# STM32WB30CEU6A register map
File version: 1.0
Registers are 32-bit, access not given, reset 0x0 unless marked. A register's access mark holds for its fields unless they carry their own. Offsets are from the block's base; [hi:lo] are bit positions; {n}, {i} and the like mark numbered series.

## SYSCFG
Base 0x40010000
Same registers: SYSCFG 0x40010100, SYSCFG 0x40010100
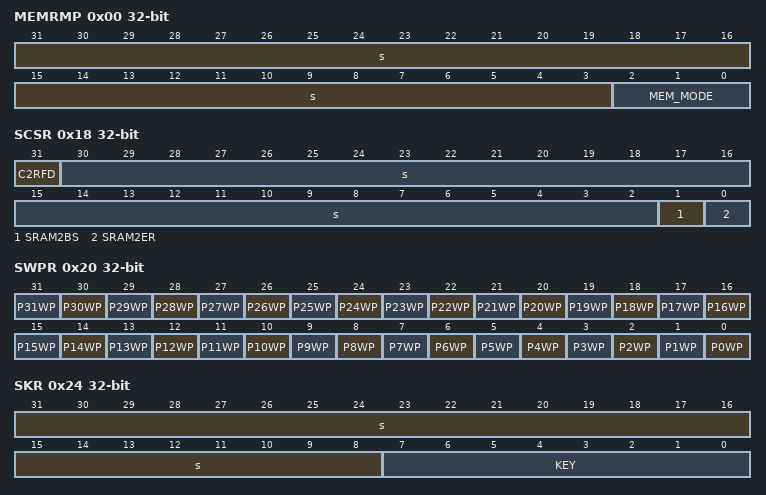
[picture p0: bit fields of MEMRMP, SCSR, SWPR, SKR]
0x00 MEMRMP
  [31:3] s, [2:0] MEM_MODE
0x04 CFGR1
  [31:26] FPU_IE, [20] I2C1_FMP, [n+10] I2C_PB{n}_FMP (n=6..9), [8] BOOSTEN, [25:0] s
0x08 EXTICR1
  [4n+2:4n] EXTI{n} (n=0..3), [31:3] s
0x0C EXTICR2
  [4n-14:4n-16] EXTI{n} (n=4..7), [31:3] s
0x10 EXTICR3
  [4n-30:4n-32] EXTI{n} (n=8..11), [31:3] s
0x14 EXTICR4
  [4n-46:4n-48] EXTI{n} (n=12..15), [31:3] s
0x18 SCSR
  [31] C2RFD, [30:2] s, [1] SRAM2BS, [0] SRAM2ER
0x1C CFGR2
  [8] SPF, [31:4] s, [3] ECCL, [2] PVDL, [1] SPL, [0] CLL
0x20 SWPR
  [n] P{n}WP (n=0..31)
0x24 SKR
  [31:8] s, [7:0] KEY
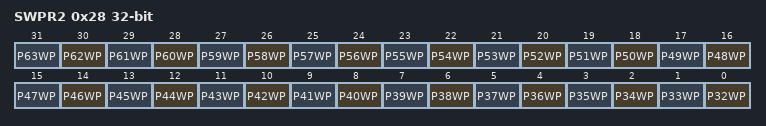
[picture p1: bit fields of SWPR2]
0x28 SWPR2
  [n-32] P{n}WP (n=32..63)
0x100 IMR1
  [n+16] EXTI{n}IM (n=5..15), [15] TIM17IM, [14] TIM16IM, [13] TIM1IM, [20:0] s
0x104 IMR2
  [20] PVDIM, [31:0] s
0x108 C2IMR1
  [n+16] EXTI{n}IM (n=0..15), [12] ADCIM, [9] RNGIM, [8] PKAIM, [6] FLASHIM, [5] RCCIM, [4] RTCALARMIM, [3] RTCWKUPIM, [15:1] s, [0] RTCSTAMPTAMPLSECSSIM
0x10C C2IMR2
  [20] PVDIM, [15] DMAMUX1IM, [31:7] s, [n-1] DMA1CH{n}IM (n=1..7)
0x110 SIPCR
  [3] SRNG, [2] SPKA, [1] SAES2, [31:0] s

## SPI1
Base 0x40013000
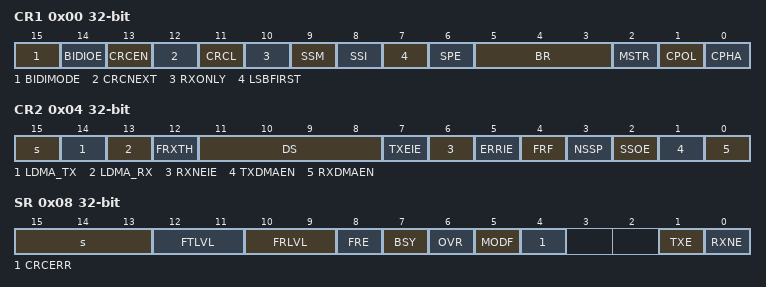
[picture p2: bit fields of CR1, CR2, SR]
0x00 CR1
  [15] BIDIMODE, [14] BIDIOE, [13] CRCEN, [12] CRCNEXT, [11] CRCL, [10] RXONLY, [9] SSM, [8] SSI, [7] LSBFIRST, [6] SPE, [5:3] BR, [2] MSTR, [1] CPOL, [0] CPHA
0x04 CR2
  [15] s, [14] LDMA_TX, [13] LDMA_RX, [12] FRXTH, [11:8] DS, [7] TXEIE, [6] RXNEIE, [5] ERRIE, [4] FRF, [3] NSSP, [2] SSOE, [1] TXDMAEN, [0] RXDMAEN
0x08 SR
  [15:13] s, [12:11] FTLVL, [10:9] FRLVL, [8] FRE, [7] BSY, [6] OVR, [5] MODF, [4] CRCERR, [1] TXE, [0] RXNE
0x0C DR
  [15:0] DR
0x10 CRCPR
  [15:0] CRCPOLY
0x14 RXCRCR
  [15:0] RXCRC
0x18 TXCRCR
  [15:0] TXCRC

## USART1
Base 0x40013800
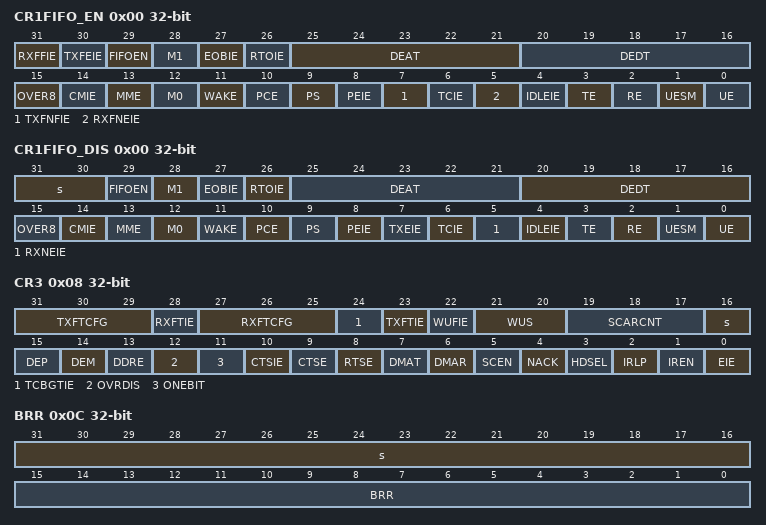
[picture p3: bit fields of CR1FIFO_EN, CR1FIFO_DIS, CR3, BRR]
0x00 CR1FIFO_EN
  [31] RXFFIE, [30] TXFEIE, [29] FIFOEN, [28] M1, [27] EOBIE, [26] RTOIE, [25:21] DEAT, [20:16] DEDT, [15] OVER8, [14] CMIE, [13] MME, [12] M0, [11] WAKE, [10] PCE, [9] PS, [8] PEIE, [7] TXFNFIE, [6] TCIE, [5] RXFNEIE, [4] IDLEIE, [3] TE, [2] RE, [1] UESM, [0] UE
0x00 CR1FIFO_DIS
  [31:30] s, [29] FIFOEN, [28] M1, [27] EOBIE, [26] RTOIE, [25:21] DEAT, [20:16] DEDT, [15] OVER8, [14] CMIE, [13] MME, [12] M0, [11] WAKE, [10] PCE, [9] PS, [8] PEIE, [7] TXEIE, [6] TCIE, [5] RXNEIE, [4] IDLEIE, [3] TE, [2] RE, [1] UESM, [0] UE
0x04 CR2
  [31:24] ADD, [23] RTOEN, [22:21] ABRMOD, [20] ABREN, [19] MSBFIRST, [18] DATAINV, [17] TXINV, [16] RXINV, [15] SWAP, [14] LINEN, [13:12] STOP, [11] CLKEN, [10] CPOL, [9] CPHA, [8] LBCL, [6] LBDIE, [5] LBDL, [4] ADDM7, [3] DIS_NSS, [7:1] s, [0] SLVEN
0x08 CR3
  [31:29] TXFTCFG, [28] RXFTIE, [27:25] RXFTCFG, [24] TCBGTIE, [23] TXFTIE, [22] WUFIE, [21:20] WUS, [19:17] SCARCNT, [16] s, [15] DEP, [14] DEM, [13] DDRE, [12] OVRDIS, [11] ONEBIT, [10] CTSIE, [9] CTSE, [8] RTSE, [7] DMAT, [6] DMAR, [5] SCEN, [4] NACK, [3] HDSEL, [2] IRLP, [1] IREN, [0] EIE
0x0C BRR
  [31:16] s, [15:0] BRR
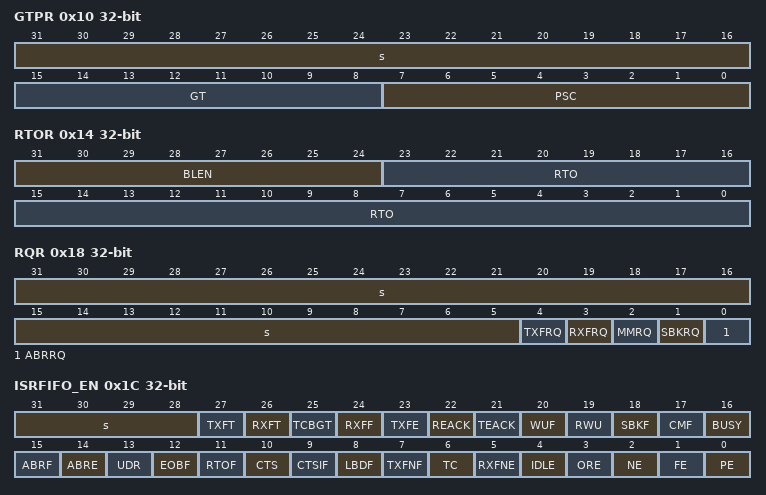
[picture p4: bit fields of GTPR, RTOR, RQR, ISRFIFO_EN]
0x10 GTPR
  [31:16] s, [15:8] GT, [7:0] PSC
0x14 RTOR
  [31:24] BLEN, [23:0] RTO
0x18 RQR
  [31:5] s, [4] TXFRQ, [3] RXFRQ, [2] MMRQ, [1] SBKRQ, [0] ABRRQ
0x1C ISRFIFO_EN
  [31:28] s, [27] TXFT, [26] RXFT, [25] TCBGT, [24] RXFF, [23] TXFE, [22] REACK, [21] TEACK, [20] WUF, [19] RWU, [18] SBKF, [17] CMF, [16] BUSY, [15] ABRF, [14] ABRE, [13] UDR, [12] EOBF, [11] RTOF, [10] CTS, [9] CTSIF, [8] LBDF, [7] TXFNF, [6] TC, [5] RXFNE, [4] IDLE, [3] ORE, [2] NE, [1] FE, [0] PE
0x1C ISRFIFO_DIS
  [25] TCBGT, [31:23] s, [22] REACK, [21] TEACK, [20] WUF, [19] RWU, [18] SBKF, [17] CMF, [16] BUSY, [15] ABRF, [14] ABRE, [13] UDR, [12] EOBF, [11] RTOF, [10] CTS, [9] CTSIF, [8] LBDF, [7] TXE, [6] TC, [5] RXNE, [4] IDLE, [3] ORE, [2] NE, [1] FE, [0] PE
0x20 ICR
  [20] WUCF, [17] CMCF, [13] UDRCF, [12] EOBCF, [11] RTOCF, [31:10] s, [9] CTSCF, [8] LBDCF, [7] TCBGTCF, [6] TCCF, [5] TXFECF, [4] IDLECF, [3] ORECF, [2] NECF, [1] FECF, [0] PECF
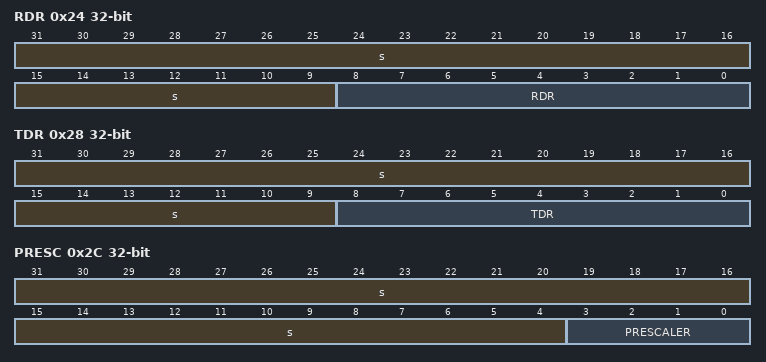
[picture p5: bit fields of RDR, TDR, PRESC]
0x24 RDR
  [31:9] s, [8:0] RDR
0x28 TDR
  [31:9] s, [8:0] TDR
0x2C PRESC
  [31:4] s, [3:0] PRESCALER
